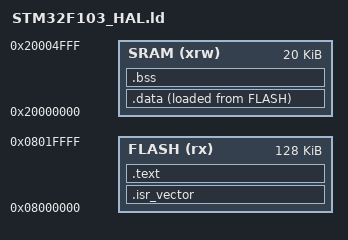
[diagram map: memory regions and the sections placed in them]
/* STM32F103xB linker script
 *   Flash : 128KB @ 0x08000000
 *   SRAM  : 20KB  @ 0x20000000
 */

ENTRY(Reset_Handler)

_estack = ORIGIN(SRAM) + LENGTH(SRAM);

MEMORY
{
  FLASH (rx)  : ORIGIN = 0x08000000, LENGTH = 128K
  SRAM (xrw)  : ORIGIN = 0x20000000, LENGTH = 20K
}

SECTIONS
{
  .isr_vector :
  {
    KEEP(*(.isr_vector))
  } >FLASH

  .text :
  {
    *(.text*)
    *(.rodata*)
    _etext = .;
  } >FLASH

  _sidata = LOADADDR(.data);
  .data :
  {
    _sdata = .;
    *(.data*)
    _edata = .;
  } >SRAM AT >FLASH

  .bss :
  {
    _sbss = .;
    *(.bss*)
    *(COMMON)
    _ebss = .;
  } >SRAM
}
